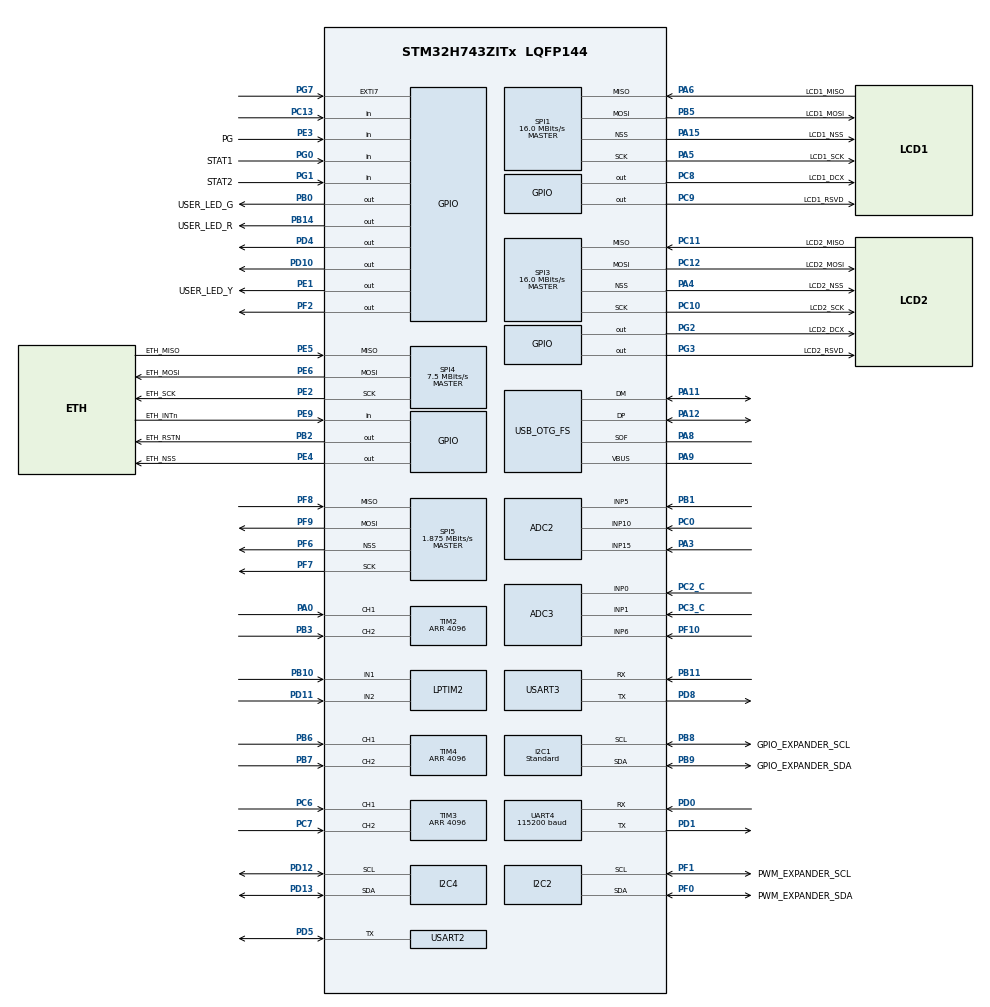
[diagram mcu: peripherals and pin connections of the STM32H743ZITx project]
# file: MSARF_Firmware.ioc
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ADC2.Channel-1\#ChannelRegularConversion=ADC_CHANNEL_15
ADC2.Channel-2\#ChannelRegularConversion=ADC_CHANNEL_5
ADC2.Channel-3\#ChannelRegularConversion=ADC_CHANNEL_5
ADC2.ContinuousConvMode=ENABLE
ADC2.ConversionDataManagement=ADC_CONVERSIONDATA_DR
ADC2.NbrOfConversion=3
ADC2.NbrOfConversionFlag=1
ADC2.OffsetNumber-1\#ChannelRegularConversion=ADC_OFFSET_NONE
ADC2.OffsetNumber-2\#ChannelRegularConversion=ADC_OFFSET_NONE
ADC2.OffsetNumber-3\#ChannelRegularConversion=ADC_OFFSET_NONE
ADC2.Rank-1\#ChannelRegularConversion=1
ADC2.Rank-2\#ChannelRegularConversion=2
ADC2.Rank-3\#ChannelRegularConversion=3
ADC2.SamplingTime-1\#ChannelRegularConversion=ADC_SAMPLETIME_64CYCLES_5
ADC2.SamplingTime-2\#ChannelRegularConversion=ADC_SAMPLETIME_64CYCLES_5
ADC2.SamplingTime-3\#ChannelRegularConversion=ADC_SAMPLETIME_64CYCLES_5
ADC3.Channel-0\#ChannelRegularConversion=ADC_CHANNEL_0
ADC3.Channel-1\#ChannelRegularConversion=ADC_CHANNEL_1
ADC3.Channel-2\#ChannelRegularConversion=ADC_CHANNEL_6
ADC3.ContinuousConvMode=ENABLE
ADC3.ConversionDataManagement=ADC_CONVERSIONDATA_DR
ADC3.EOCSelection=ADC_EOC_SINGLE_CONV
ADC3.NbrOfConversion=3
ADC3.NbrOfConversionFlag=1
ADC3.OffsetNumber-0\#ChannelRegularConversion=ADC_OFFSET_NONE
ADC3.OffsetNumber-1\#ChannelRegularConversion=ADC_OFFSET_NONE
ADC3.OffsetNumber-2\#ChannelRegularConversion=ADC_OFFSET_NONE
ADC3.Rank-0\#ChannelRegularConversion=1
ADC3.Rank-1\#ChannelRegularConversion=2
ADC3.Rank-2\#ChannelRegularConversion=3
ADC3.SamplingTime-0\#ChannelRegularConversion=ADC_SAMPLETIME_64CYCLES_5
ADC3.SamplingTime-1\#ChannelRegularConversion=ADC_SAMPLETIME_64CYCLES_5
ADC3.SamplingTime-2\#ChannelRegularConversion=ADC_SAMPLETIME_64CYCLES_5
CORTEX_M7.CPU_DCache=Enabled
CORTEX_M7.CPU_ICache=Enabled
CORTEX_M7.MPU_Control=MPU_PRIVILEGED_DEFAULT
DMA2D.ColorMode=DMA2D_OUTPUT_ARGB1555
Dma.Request0=SPI1_TX
Dma.Request1=SPI3_TX
Dma.SPI1_TX.0.Direction=DMA_MEMORY_TO_PERIPH
Dma.SPI1_TX.0.EventEnable=DISABLE
Dma.SPI1_TX.0.FIFOMode=DMA_FIFOMODE_DISABLE
Dma.SPI1_TX.0.Instance=DMA1_Stream4
Dma.SPI1_TX.0.MemDataAlignment=DMA_MDATAALIGN_BYTE
Dma.SPI1_TX.0.MemInc=DMA_MINC_ENABLE
Dma.SPI1_TX.0.Mode=DMA_NORMAL
Dma.SPI1_TX.0.PeriphDataAlignment=DMA_PDATAALIGN_BYTE
Dma.SPI1_TX.0.PeriphInc=DMA_PINC_DISABLE
Dma.SPI1_TX.0.Polarity=HAL_DMAMUX_REQ_GEN_RISING
Dma.SPI1_TX.0.Priority=DMA_PRIORITY_LOW
Dma.SPI1_TX.0.RequestNumber=1
Dma.SPI1_TX.0.SignalID=NONE
Dma.SPI1_TX.0.SyncEnable=DISABLE
Dma.SPI1_TX.0.SyncPolarity=HAL_DMAMUX_SYNC_NO_EVENT
Dma.SPI1_TX.0.SyncRequestNumber=1
Dma.SPI1_TX.0.SyncSignalID=NONE
Dma.SPI3_TX.1.Direction=DMA_MEMORY_TO_PERIPH
Dma.SPI3_TX.1.EventEnable=DISABLE
Dma.SPI3_TX.1.FIFOMode=DMA_FIFOMODE_DISABLE
Dma.SPI3_TX.1.Instance=DMA1_Stream0
Dma.SPI3_TX.1.MemDataAlignment=DMA_MDATAALIGN_BYTE
Dma.SPI3_TX.1.MemInc=DMA_MINC_ENABLE
Dma.SPI3_TX.1.Mode=DMA_NORMAL
Dma.SPI3_TX.1.PeriphDataAlignment=DMA_PDATAALIGN_BYTE
Dma.SPI3_TX.1.PeriphInc=DMA_PINC_DISABLE
Dma.SPI3_TX.1.Polarity=HAL_DMAMUX_REQ_GEN_RISING
Dma.SPI3_TX.1.Priority=DMA_PRIORITY_LOW
Dma.SPI3_TX.1.RequestNumber=1
Dma.SPI3_TX.1.SignalID=NONE
Dma.SPI3_TX.1.SyncEnable=DISABLE
Dma.SPI3_TX.1.SyncPolarity=HAL_DMAMUX_SYNC_NO_EVENT
Dma.SPI3_TX.1.SyncRequestNumber=1
Dma.SPI3_TX.1.SyncSignalID=NONE
FREERTOS.BinarySemaphores01=lcdDisplaysTaskSem,Dynamic,NULL;pidStepTaskSem,Dynamic,NULL
FREERTOS.HEAP_NUMBER=4
FREERTOS.INCLUDE_pcTaskGetTaskName=1
FREERTOS.INCLUDE_uxTaskGetStackHighWaterMark2=1
FREERTOS.INCLUDE_xTaskGetCurrentTaskHandle=1
FREERTOS.INCLUDE_xTaskGetHandle=1
FREERTOS.Tasks01=commTask,24,2048,StartCommTask,Default,NULL,Dynamic,NULL,NULL;lcdDisplaysTask,24,4096,StartLCDDisplays,Default,NULL,Dynamic,NULL,NULL;motorOutputTask,24,4096,StartMotorOutput,Default,NULL,Dynamic,NULL,NULL
FREERTOS.Timers01=Timer_LCD,Timer_LCD_cb,osTimerPeriodic,Default,NULL,Dynamic,NULL;Timer_PID,Timer_PID_cb,osTimerPeriodic,Default,NULL,Dynamic,NULL
FREERTOS.configENABLE_FPU=1
FREERTOS.configGENERATE_RUN_TIME_STATS=1
FREERTOS.configRECORD_STACK_HIGH_ADDRESS=1
FREERTOS.configTIMER_TASK_PRIORITY=55
FREERTOS.configTOTAL_HEAP_SIZE=512000
FREERTOS.configUSE_APPLICATION_TASK_TAG=1
FREERTOS.configUSE_STATS_FORMATTING_FUNCTIONS=1
HRTIM.CompareUnit1-MasterTimer=__NULL
HRTIM.Periode_MASTER=12000
HRTIM.PrescalerRatio_MASTER=HRTIM_PRESCALERRATIO_DIV1
I2C1.AddressingMode=I2C_ADDRESSINGMODE_7BIT
I2C1.I2C_Speed_Mode=I2C_Standard
I2C1.Timing=0x307075B1
I2C2.Timing=0x307075B1
I2C4.Timing=0x307075B1
Mcu.Family=STM32H7
Mcu.Name=STM32H743ZITx
Mcu.Package=LQFP144
NVIC.DMA1_Stream0_IRQn=true\:5\:0\:false\:false\:true\:true\:false\:true
NVIC.DMA1_Stream4_IRQn=true\:5\:0\:false\:false\:true\:true\:false\:true
NVIC.HRTIM1_Master_IRQn=true\:5\:0\:false\:false\:true\:true\:true\:true
NVIC.PriorityGroup=NVIC_PRIORITYGROUP_4
NVIC.SPI1_IRQn=true\:5\:0\:false\:false\:true\:true\:false\:true
NVIC.SPI3_IRQn=true\:5\:0\:false\:false\:true\:true\:false\:true
NVIC.TIM1_UP_IRQn=true\:0\:0\:false\:false\:true\:false\:false\:true
NVIC.TimeBase=TIM1_UP_IRQn
NVIC.TimeBaseIP=TIM1
PA0.Signal=S_TIM2_CH1_ETR
PA11.Mode=Device_Only
PA11.Signal=USB_OTG_FS_DM
PA12.Mode=Device_Only
PA12.Signal=USB_OTG_FS_DP
PA15\ (JTDI).GPIO_Label=LCD1_NSS
PA15\ (JTDI).Mode=NSS_Signal_Hard_Output
PA15\ (JTDI).Signal=SPI1_NSS
PA3.Signal=ADCx_INP15
PA4.GPIO_Label=LCD2_NSS
PA4.Mode=NSS_Signal_Hard_Output
PA4.Signal=SPI3_NSS
PA5.GPIO_Label=LCD1_SCK
PA5.Mode=Full_Duplex_Master
PA5.Signal=SPI1_SCK
PA6.GPIO_Label=LCD1_MISO
PA6.Mode=Full_Duplex_Master
PA6.Signal=SPI1_MISO
PA8.Mode=Activate_SOF_FS
PA8.Signal=USB_OTG_FS_SOF
PA9.Mode=Activate_VBUS
PA9.Signal=USB_OTG_FS_VBUS
PB0.GPIO_Label=USER_LED_G
PB0.Signal=GPIO_Output
PB1.Signal=ADCx_INP5
PB10.Mode=Encoder_mode_occur1
PB10.Signal=LPTIM2_IN1
PB11.Mode=Asynchronous
PB11.Signal=USART3_RX
PB14.GPIO_Label=USER_LED_R
PB14.GPIO_ModeDefaultOutputPP=GPIO_MODE_OUTPUT_PP
PB14.GPIO_PuPd=GPIO_NOPULL
PB14.GPIO_Speed=GPIO_SPEED_FREQ_LOW
PB14.PinState=GPIO_PIN_RESET
PB14.Signal=GPIO_Output
PB2.GPIO_Label=ETH_RSTN
PB2.GPIO_ModeDefaultOutputPP=GPIO_MODE_OUTPUT_PP
PB2.GPIO_PuPd=GPIO_NOPULL
PB2.GPIO_Speed=GPIO_SPEED_FREQ_LOW
PB2.PinState=GPIO_PIN_RESET
PB2.Signal=GPIO_Output
PB3\ (JTDO/TRACESWO).Signal=S_TIM2_CH2
PB5.GPIO_Label=LCD1_MOSI
PB5.Mode=Full_Duplex_Master
PB5.Signal=SPI1_MOSI
PB6.Signal=S_TIM4_CH1
PB7.Signal=S_TIM4_CH2
PB8.GPIO_Label=GPIO_EXPANDER_SCL
PB8.Mode=I2C
PB8.Signal=I2C1_SCL
PB9.GPIO_Label=GPIO_EXPANDER_SDA
PB9.Mode=I2C
PB9.Signal=I2C1_SDA
PC0.Signal=ADCx_INP10
PC10.GPIO_Label=LCD2_SCK
PC10.Mode=Full_Duplex_Master
PC10.Signal=SPI3_SCK
PC11.GPIO_Label=LCD2_MISO
PC11.Mode=Full_Duplex_Master
PC11.Signal=SPI3_MISO
PC12.GPIO_Label=LCD2_MOSI
PC12.Mode=Full_Duplex_Master
PC12.Signal=SPI3_MOSI
PC13.GPIO_Mode=GPIO_MODE_INPUT
PC13.GPIO_PuPd=GPIO_NOPULL
PC13.Signal=GPIO_Input
PC14-OSC32_IN\ (OSC32_IN).Mode=LSE-External-Oscillator
PC14-OSC32_IN\ (OSC32_IN).Signal=RCC_OSC32_IN
PC15-OSC32_OUT\ (OSC32_OUT).Mode=LSE-External-Oscillator
PC15-OSC32_OUT\ (OSC32_OUT).Signal=RCC_OSC32_OUT
PC2_C.Mode=IN0-Single-Ended
PC2_C.Signal=ADC3_INP0
PC3_C.Mode=IN1-Single-Ended
PC3_C.Signal=ADC3_INP1
PC6.Signal=S_TIM3_CH1
PC7.Signal=S_TIM3_CH2
PC8.GPIO_Label=LCD1_DCX
PC8.GPIO_ModeDefaultOutputPP=GPIO_MODE_OUTPUT_PP
PC8.GPIO_PuPd=GPIO_NOPULL
PC8.GPIO_Speed=GPIO_SPEED_FREQ_LOW
PC8.PinState=GPIO_PIN_RESET
PC8.Signal=GPIO_Output
PC9.GPIO_Label=LCD1_RSVD
PC9.GPIO_ModeDefaultOutputPP=GPIO_MODE_OUTPUT_PP
PC9.GPIO_PuPd=GPIO_NOPULL
PC9.GPIO_Speed=GPIO_SPEED_FREQ_LOW
PC9.PinState=GPIO_PIN_RESET
PC9.Signal=GPIO_Output
PD0.GPIO_PuPd=GPIO_NOPULL
PD0.GPIO_Speed=GPIO_SPEED_FREQ_LOW
PD0.Mode=Asynchronous
PD0.Signal=UART4_RX
PD1.GPIO_PuPd=GPIO_NOPULL
PD1.GPIO_Speed=GPIO_SPEED_FREQ_VERY_HIGH
PD1.Mode=Asynchronous
PD1.Signal=UART4_TX
PD10.GPIO_ModeDefaultOutputPP=GPIO_MODE_OUTPUT_PP
PD10.GPIO_PuPd=GPIO_NOPULL
PD10.GPIO_Speed=GPIO_SPEED_FREQ_LOW
PD10.PinState=GPIO_PIN_RESET
PD10.Signal=GPIO_Output
PD11.Mode=Encoder_mode_occur1
PD11.Signal=LPTIM2_IN2
PD12.Mode=I2C
PD12.Signal=I2C4_SCL
PD13.Mode=I2C
PD13.Signal=I2C4_SDA
PD4.PinState=GPIO_PIN_SET
PD4.Signal=GPIO_Output
PD5.Mode=Half_duplex(single_wire_mode)
PD5.Signal=USART2_TX
PD6.Signal=USART2_RX
PD7.Signal=USART2_CK
PD8.Mode=Asynchronous
PD8.Signal=USART3_TX
PE1.GPIO_Label=USER_LED_Y
PE1.Signal=GPIO_Output
PE2.GPIO_Label=ETH_SCK
PE2.Mode=Full_Duplex_Master
PE2.Signal=SPI4_SCK
PE3.GPIO_Label=PG
PE3.GPIO_Mode=GPIO_MODE_INPUT
PE3.GPIO_PuPd=GPIO_PULLUP
PE3.Signal=GPIO_Input
PE4.GPIO_Label=ETH_NSS
PE4.GPIO_ModeDefaultOutputPP=GPIO_MODE_OUTPUT_PP
PE4.GPIO_PuPd=GPIO_PULLUP
PE4.GPIO_Speed=GPIO_SPEED_FREQ_LOW
PE4.PinState=GPIO_PIN_RESET
PE4.Signal=GPIO_Output
PE5.GPIO_Label=ETH_MISO
PE5.Mode=Full_Duplex_Master
PE5.Signal=SPI4_MISO
PE6.GPIO_Label=ETH_MOSI
PE6.Mode=Full_Duplex_Master
PE6.Signal=SPI4_MOSI
PE9.GPIO_Label=ETH_INTn
PE9.GPIO_Mode=GPIO_MODE_INPUT
PE9.GPIO_PuPd=GPIO_NOPULL
PE9.Signal=GPIO_Input
PF0.GPIO_Label=PWM_EXPANDER_SDA
PF0.Mode=I2C
PF0.Signal=I2C2_SDA
PF1.GPIO_Label=PWM_EXPANDER_SCL
PF1.Mode=I2C
PF1.Signal=I2C2_SCL
PF10.Mode=IN6-Single-Ended
PF10.Signal=ADC3_INP6
PF2.Signal=GPIO_Output
PF6.Mode=NSS_Signal_Hard_Output
PF6.Signal=SPI5_NSS
PF7.GPIO_PuPd=GPIO_NOPULL
PF7.Mode=Full_Duplex_Master
PF7.Signal=SPI5_SCK
PF8.GPIO_PuPd=GPIO_PULLDOWN
PF8.Mode=Full_Duplex_Master
PF8.Signal=SPI5_MISO
PF9.GPIO_PuPd=GPIO_PULLDOWN
PF9.Mode=Full_Duplex_Master
PF9.Signal=SPI5_MOSI
PG0.GPIO_Label=STAT1
PG0.GPIO_PuPd=GPIO_PULLUP
PG0.Signal=GPIO_Input
PG1.GPIO_Label=STAT2
PG1.GPIO_Mode=GPIO_MODE_INPUT
PG1.GPIO_PuPd=GPIO_PULLUP
PG1.Signal=GPIO_Input
PG2.GPIO_Label=LCD2_DCX
PG2.Signal=GPIO_Output
PG3.GPIO_Label=LCD2_RSVD
PG3.GPIO_ModeDefaultOutputPP=GPIO_MODE_OUTPUT_PP
PG3.GPIO_PuPd=GPIO_NOPULL
PG3.GPIO_Speed=GPIO_SPEED_FREQ_LOW
PG3.PinState=GPIO_PIN_RESET
PG3.Signal=GPIO_Output
PG7.GPIO_ModeDefaultEXTI=GPIO_MODE_IT_RISING
PG7.GPIO_PuPd=GPIO_NOPULL
PG7.Signal=GPXTI7
PH0-OSC_IN\ (PH0).Mode=HSE-External-Oscillator
PH0-OSC_IN\ (PH0).Signal=RCC_OSC_IN
PH1-OSC_OUT\ (PH1).Mode=HSE-External-Oscillator
PH1-OSC_OUT\ (PH1).Signal=RCC_OSC_OUT
ProjectManager.HeapSize=0x200
ProjectManager.StackSize=0x400
ProjectManager.TargetToolchain=STM32CubeIDE
RCC.ADCFreq_Value=76000000
RCC.APB1Freq_Value=120000000
RCC.APB2Freq_Value=120000000
RCC.APB3Freq_Value=120000000
RCC.APB4Freq_Value=120000000
RCC.CortexFreq_Value=480000000
RCC.D1PPRE=RCC_APB3_DIV2
RCC.D2PPRE1=RCC_APB1_DIV2
RCC.D2PPRE2=RCC_APB2_DIV2
RCC.D3PPRE=RCC_APB4_DIV2
RCC.DIVM1=1
RCC.DIVM2=1
RCC.DIVN1=120
RCC.DIVN2=19
RCC.DIVQ1=20
RCC.HCLKFreq_Value=240000000
RCC.HPRE=RCC_HCLK_DIV2
RCC.HSE_VALUE=8000000
RCC.PLL2FRACN=0
RCC.PLL3FRACN=0
RCC.PLLFRACN=0
RCC.RCC_TIM_PRescaler_Selection=RCC_TIMPRES_DESACTIVATED
RCC.SPI123CLockSelection=RCC_SPI123CLKSOURCE_CLKP
RCC.SYSCLKFreq_VALUE=480000000
RCC.SYSCLKSource=RCC_SYSCLKSOURCE_PLLCLK
RCC.USBFreq_Value=48000000
SH.ADCx_INP10.0=ADC2_INP10,IN10-Single-Ended
SH.ADCx_INP15.0=ADC2_INP15,IN15-Single-Ended
SH.ADCx_INP5.0=ADC2_INP5,IN5-Single-Ended
SH.S_TIM2_CH1_ETR.0=TIM2_CH1,Encoder_Interface
SH.S_TIM2_CH2.0=TIM2_CH2,Encoder_Interface
SH.S_TIM3_CH1.0=TIM3_CH1,Encoder_Interface
SH.S_TIM3_CH2.0=TIM3_CH2,Encoder_Interface
SH.S_TIM4_CH1.0=TIM4_CH1,Encoder_Interface
SH.S_TIM4_CH2.0=TIM4_CH2,Encoder_Interface
SPI1.BaudRatePrescaler=SPI_BAUDRATEPRESCALER_4
SPI1.CLKPolarity=SPI_POLARITY_LOW
SPI1.CalculateBaudRate=16.0 MBits/s
SPI1.DataSize=SPI_DATASIZE_8BIT
SPI1.Direction=SPI_DIRECTION_2LINES
SPI1.FirstBit=SPI_FIRSTBIT_MSB
SPI1.Mode=SPI_MODE_MASTER
SPI1.VirtualNSS=VM_NSSHARD
SPI1.VirtualType=VM_MASTER
SPI3.BaudRatePrescaler=SPI_BAUDRATEPRESCALER_4
SPI3.CalculateBaudRate=16.0 MBits/s
SPI3.DataSize=SPI_DATASIZE_8BIT
SPI3.Direction=SPI_DIRECTION_2LINES
SPI3.Mode=SPI_MODE_MASTER
SPI3.VirtualNSS=VM_NSSHARD
SPI3.VirtualType=VM_MASTER
SPI4.BaudRatePrescaler=SPI_BAUDRATEPRESCALER_16
SPI4.CLKPhase=SPI_PHASE_2EDGE
SPI4.CLKPolarity=SPI_POLARITY_HIGH
SPI4.CalculateBaudRate=7.5 MBits/s
SPI4.DataSize=SPI_DATASIZE_8BIT
SPI4.Direction=SPI_DIRECTION_2LINES
SPI4.Mode=SPI_MODE_MASTER
SPI4.VirtualType=VM_MASTER
SPI5.BaudRatePrescaler=SPI_BAUDRATEPRESCALER_64
SPI5.CLKPhase=SPI_PHASE_2EDGE
SPI5.CLKPolarity=SPI_POLARITY_LOW
SPI5.CalculateBaudRate=1.875 MBits/s
SPI5.DataSize=SPI_DATASIZE_8BIT
SPI5.Direction=SPI_DIRECTION_2LINES
SPI5.MasterKeepIOState=SPI_MASTER_KEEP_IO_STATE_ENABLE
SPI5.Mode=SPI_MODE_MASTER
SPI5.VirtualNSS=VM_NSSHARD
SPI5.VirtualType=VM_MASTER
TIM2.IC1Filter=5
TIM2.IC2Filter=5
TIM2.Period=4096
TIM3.IC1Filter=5
TIM3.IC2Filter=5
TIM3.Period=4096
TIM4.IC1Filter=5
TIM4.IC2Filter=5
TIM4.Period=4096
UART4.BaudRate=115200
UART4.ClockPrescaler=PRESCALER_DIV1
UART4.DMADisableonRxErrorParam=UART_ADVFEATURE_DMA_ENABLEONRXERROR
UART4.FIFOMode=FIFOMODE_ENABLE
UART4.OverrunDisableParam=UART_ADVFEATURE_OVERRUN_ENABLE
UART4.RXFIFOThreshold=RXFIFO_THRESHOLD_HALFFULL
UART4.RxPinLevelInvertParam=UART_ADVFEATURE_RXINV_DISABLE
UART4.SwapParam=UART_ADVFEATURE_SWAP_DISABLE
UART4.TXFIFOThreshold=TXFIFO_THRESHOLD_HALFFULL
UART4.WordLength=WORDLENGTH_8B
USART2.VirtualMode-Half_duplex(single_wire_mode)=VM_ASYNC
USART3.VirtualMode-Asynchronous=VM_ASYNC
USB_OTG_FS.VirtualMode=Device_Only
VP_DMA2D_VS_DMA2D.Mode=DMA2D_Activate
VP_FREERTOS_VS_CMSIS_V2.Mode=CMSIS_V2
VP_HRTIM_VS_hrtimMasterTimerNoOutput.Mode=MasterTimer
VP_SYS_VS_tim1.Mode=TIM1
board=NUCLEO-H743ZI2

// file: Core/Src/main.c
/* USER CODE BEGIN Header */
/**
 ******************************************************************************
 * @file           : main.c
 * @brief          : Main program body
 ******************************************************************************
 * @attention
 *
 * <h2><center>&copy; Copyright (c) 2019 STMicroelectronics.
 * All rights reserved.</center></h2>
 *
 * This software component is licensed by ST under BSD 3-Clause license,
 * the "License"; You may not use this file except in compliance with the
 * License. You may obtain a copy of the License at:
 *                        opensource.org/licenses/BSD-3-Clause
 *
 ******************************************************************************
 */
/* USER CODE END Header */
#include "main.h"
#include "cmsis_os.h"

/* USER CODE BEGIN Includes */
#include "ST7789Wrapper.h"

#include "Xavier.h"

#include "PackageWrapper.h"

#include "Ethernet_Driver.h"
#include "eye_80x80.h"

#include <stdlib.h>
#include <stdio.h>
/* USER CODE END Includes */

/* USER CODE BEGIN PD */
#define ever ;;
//#define DO_LOOP_MEASURE 1
/* USER CODE END PD */

ADC_HandleTypeDef hadc2;
ADC_HandleTypeDef hadc3;

DMA2D_HandleTypeDef hdma2d;

HRTIM_HandleTypeDef hhrtim;

I2C_HandleTypeDef hi2c1;
I2C_HandleTypeDef hi2c2;
I2C_HandleTypeDef hi2c4;

LPTIM_HandleTypeDef hlptim2;

SPI_HandleTypeDef hspi1;
SPI_HandleTypeDef hspi3;
SPI_HandleTypeDef hspi4;
SPI_HandleTypeDef hspi5;
DMA_HandleTypeDef hdma_spi1_tx;
DMA_HandleTypeDef hdma_spi3_tx;

TIM_HandleTypeDef htim2;
TIM_HandleTypeDef htim3;
TIM_HandleTypeDef htim4;

UART_HandleTypeDef huart4;
UART_HandleTypeDef huart2;
UART_HandleTypeDef huart3;

USART_HandleTypeDef husart2;

PCD_HandleTypeDef hpcd_USB_OTG_FS;

/* Definitions for commTask */
osThreadId_t commTaskHandle;
const osThreadAttr_t commTask_attributes = {
  .name = "commTask",
  .stack_size = 2048 * 4,
  .priority = (osPriority_t) osPriorityNormal,
};
/* Definitions for lcdDisplaysTask */
osThreadId_t lcdDisplaysTaskHandle;
const osThreadAttr_t lcdDisplaysTask_attributes = {
  .name = "lcdDisplaysTask",
  .stack_size = 4096 * 4,
  .priority = (osPriority_t) osPriorityNormal,
};
/* Definitions for motorOutputTask */
osThreadId_t motorOutputTaskHandle;
const osThreadAttr_t motorOutputTask_attributes = {
  .name = "motorOutputTask",
  .stack_size = 4096 * 4,
  .priority = (osPriority_t) osPriorityNormal,
};
/* Definitions for Timer_LCD */
osTimerId_t Timer_LCDHandle;
const osTimerAttr_t Timer_LCD_attributes = {
  .name = "Timer_LCD"
};
/* Definitions for Timer_PID */
osTimerId_t Timer_PIDHandle;
const osTimerAttr_t Timer_PID_attributes = {
  .name = "Timer_PID"
};
/* Definitions for lcdDisplaysTaskSem */
osSemaphoreId_t lcdDisplaysTaskSemHandle;
const osSemaphoreAttr_t lcdDisplaysTaskSem_attributes = {
  .name = "lcdDisplaysTaskSem"
};
/* Definitions for pidStepTaskSem */
osSemaphoreId_t pidStepTaskSemHandle;
const osSemaphoreAttr_t pidStepTaskSem_attributes = {
  .name = "pidStepTaskSem"
};

void SystemClock_Config(void);
void PeriphCommonClock_Config(void);
static void MPU_Config(void);
static void MX_GPIO_Init(void);
static void MX_DMA_Init(void);
static void MX_USB_OTG_FS_PCD_Init(void);
static void MX_SPI4_Init(void);
static void MX_SPI1_Init(void);
static void MX_DMA2D_Init(void);
static void MX_I2C1_Init(void);
static void MX_I2C2_Init(void);
static void MX_UART4_Init(void);
static void MX_LPTIM2_Init(void);
static void MX_SPI3_Init(void);
static void MX_SPI5_Init(void);
static void MX_USART2_UART_Init(void);
static void MX_I2C4_Init(void);
static void MX_TIM2_Init(void);
static void MX_TIM3_Init(void);
static void MX_TIM4_Init(void);
static void MX_HRTIM_Init(void);
static void MX_ADC3_Init(void);
static void MX_USART3_UART_Init(void);
static void MX_ADC2_Init(void);
void StartCommTask(void *argument);
void StartLCDDisplays(void *argument);
void StartMotorOutput(void *argument);
void Timer_LCD_cb(void *argument);
void Timer_PID_cb(void *argument);

/* USER CODE BEGIN PFP */
void FillRectHandle(void);
void BlendImageHandle(void);
/* USER CODE END PFP */

/* USER CODE BEGIN 0 */
uint8_t generic_st7789[] = {      // Init commands for 7789 screens
		9,                                  //  9 commands in list:
				ST77XX_SWRESET, ST_CMD_DELAY, //  1: Software reset, no args, w/delay
				150,                            //     ~150 ms delay
				ST77XX_SLPOUT, ST_CMD_DELAY, //  2: Out of sleep mode, no args, w/delay
				10,                             //      10 ms delay
				ST77XX_COLMOD, 1 + ST_CMD_DELAY, //  3: Set color mode, 1 arg + delay:
				0x55,                           //     16-bit color
				10,                             //     10 ms delay
				ST77XX_MADCTL, 1, //  4: Mem access ctrl (directions), 1 arg:
				0x58,                //     Row/col addr, bottom-top refresh
				ST77XX_CASET, 4,   //  5: Column addr set, 4 args, no delay:
				0x00, 0,                        //     XSTART = 0
				0, 240,                         //     XEND = 240
				ST77XX_RASET, 4,      //  6: Row addr set, 4 args, no delay:
				0x00, 0,                        //     YSTART = 0
				320 >> 8, 320 & 0xFF,                     //     YEND = 320
				ST77XX_INVON, ST_CMD_DELAY,         //  7: hack
				10,
				ST77XX_NORON, ST_CMD_DELAY, //  8: Normal display on, no args, w/delay
				10,                             //     10 ms delay
				ST77XX_DISPON, ST_CMD_DELAY, //  9: Main screen turn on, no args, delay
				10 };

struct ST7789 *lcd1;
struct ST7789 *lcd2;

struct GPIOBank *_GPIOBank;
struct PWMBank *_PWMBank;

#define MAX_PACKAGES 255
struct Package *Packages[MAX_PACKAGES];

uint16_t *lcd1_screen_buffer;
uint16_t *lcd2_screen_buffer;

int32_t timer_count = 0;

uint32_t ADC_buff[6];
uint32_t val[6];

DMA2D_HandleTypeDef fillRectHandle;
DMA2D_HandleTypeDef blendImageHandle;

uint8_t lcd1_x_t = 50;
uint8_t lcd1_y_t = 50;
uint8_t lcd2_x_t = 50;
uint8_t lcd2_y_t = 50;

uint8_t blink = 0;

//void HAL_ADC_ConvCpltCallback(ADC_HandleTypeDef *hadc){
//	if(hadc->Instance == ADC2){
//		val[0] = ADC_buff[0];
//		val[1] = ADC_buff[1];
//		val[2] = ADC_buff[2];
//	}else if(hadc->Instance == ADC3){
//		val[3] = ADC_buff[3];
//		val[4] = ADC_buff[4];
//		val[5] = ADC_buff[5];
//	}
//}

volatile bool oneTransmitting = false;
volatile bool threeTransmitting = false;

void HAL_SPI_TxCpltCallback(SPI_HandleTypeDef *hspi){
	if(hspi->Instance == SPI1){
		oneTransmitting = false;
	}else if(hspi->Instance == SPI3){
		threeTransmitting = false;
	}
}

/* USER CODE END 0 */

int main(void)
{

  /* MPU Configuration--------------------------------------------------------*/
  MPU_Config();

  /* Enable I-Cache---------------------------------------------------------*/
  SCB_EnableICache();

  /* Enable D-Cache---------------------------------------------------------*/
  SCB_EnableDCache();

  /* MCU Configuration--------------------------------------------------------*/

  /* Reset of all peripherals, Initializes the Flash interface and the Systick. */
  HAL_Init();

  /* Configure the system clock */
  SystemClock_Config();

/* Configure the peripherals common clocks */
  PeriphCommonClock_Config();

  /* Initialize all configured peripherals */
  MX_GPIO_Init();
  MX_DMA_Init();
  MX_USB_OTG_FS_PCD_Init();
  MX_SPI4_Init();
  MX_SPI1_Init();
  MX_DMA2D_Init();
  MX_I2C1_Init();
  MX_I2C2_Init();
  MX_UART4_Init();
  MX_LPTIM2_Init();
  MX_SPI3_Init();
  MX_SPI5_Init();
  MX_USART2_UART_Init();
  MX_I2C4_Init();
  MX_TIM2_Init();
  MX_TIM3_Init();
  MX_TIM4_Init();
  MX_HRTIM_Init();
  MX_ADC3_Init();
  MX_USART3_UART_Init();
  MX_ADC2_Init();
  /* USER CODE BEGIN 2 */
  FillRectHandle();
  BlendImageHandle();

	HAL_HRTIM_SimpleBaseStart_IT(&hhrtim, HRTIM_TIMERINDEX_MASTER);
  /* USER CODE END 2 */

  /* Init scheduler */
  osKernelInitialize();

  /* Create the semaphores(s) */
  /* creation of lcdDisplaysTaskSem */
  lcdDisplaysTaskSemHandle = osSemaphoreNew(1, 1, &lcdDisplaysTaskSem_attributes);

  /* creation of pidStepTaskSem */
  pidStepTaskSemHandle = osSemaphoreNew(1, 1, &pidStepTaskSem_attributes);

  /* Create the timer(s) */
  /* creation of Timer_LCD */
  Timer_LCDHandle = osTimerNew(Timer_LCD_cb, osTimerPeriodic, NULL, &Timer_LCD_attributes);

  /* creation of Timer_PID */
  Timer_PIDHandle = osTimerNew(Timer_PID_cb, osTimerPeriodic, NULL, &Timer_PID_attributes);

  /* USER CODE BEGIN RTOS_TIMERS */
	osStatus Timer_LCD_status = osTimerStart(Timer_LCDHandle, 33u);
	if(Timer_LCD_status != osOK){
	//timer didnt start
		timer_count = -1;
	}

	osStatus Timer_PID_status = osTimerStart(Timer_PIDHandle, 30u);
	if(Timer_PID_status != osOK){
	//timer didnt start
		timer_count = -1;
	}

	/* start timers, add new ones, ... */
  /* USER CODE END RTOS_TIMERS */

  /* Create the thread(s) */
  /* creation of commTask */
  commTaskHandle = osThreadNew(StartCommTask, NULL, &commTask_attributes);

  /* creation of lcdDisplaysTask */
  lcdDisplaysTaskHandle = osThreadNew(StartLCDDisplays, NULL, &lcdDisplaysTask_attributes);

  /* creation of motorOutputTask */
  motorOutputTaskHandle = osThreadNew(StartMotorOutput, NULL, &motorOutputTask_attributes);

  /* USER CODE BEGIN RTOS_THREADS */
	osThreadSuspend(lcdDisplaysTaskHandle);
	osThreadSuspend(motorOutputTaskHandle);
	/* add threads, ... */
  /* USER CODE END RTOS_THREADS */

  /* Start scheduler */
  osKernelStart();

  /* We should never get here as control is now taken by the scheduler */
  /* Infinite loop */
	while (1) {

	}
}

void SystemClock_Config(void)
{
  RCC_OscInitTypeDef RCC_OscInitStruct = {0};
  RCC_ClkInitTypeDef RCC_ClkInitStruct = {0};

  /** Supply configuration update enable
  */
  HAL_PWREx_ConfigSupply(PWR_LDO_SUPPLY);
  /** Configure the main internal regulator output voltage
  */
  __HAL_PWR_VOLTAGESCALING_CONFIG(PWR_REGULATOR_VOLTAGE_SCALE0);

  while(!__HAL_PWR_GET_FLAG(PWR_FLAG_VOSRDY)) {}
  /** Macro to configure the PLL clock source
  */
  __HAL_RCC_PLL_PLLSOURCE_CONFIG(RCC_PLLSOURCE_HSE);
  /** Initializes the RCC Oscillators according to the specified parameters
  * in the RCC_OscInitTypeDef structure.
  */
  RCC_OscInitStruct.OscillatorType = RCC_OSCILLATORTYPE_HSI|RCC_OSCILLATORTYPE_HSE;
  RCC_OscInitStruct.HSEState = RCC_HSE_ON;
  RCC_OscInitStruct.HSIState = RCC_HSI_DIV1;
  RCC_OscInitStruct.HSICalibrationValue = RCC_HSICALIBRATION_DEFAULT;
  RCC_OscInitStruct.PLL.PLLState = RCC_PLL_ON;
  RCC_OscInitStruct.PLL.PLLSource = RCC_PLLSOURCE_HSE;
  RCC_OscInitStruct.PLL.PLLM = 1;
  RCC_OscInitStruct.PLL.PLLN = 120;
  RCC_OscInitStruct.PLL.PLLP = 2;
  RCC_OscInitStruct.PLL.PLLQ = 20;
  RCC_OscInitStruct.PLL.PLLR = 2;
  RCC_OscInitStruct.PLL.PLLRGE = RCC_PLL1VCIRANGE_3;
  RCC_OscInitStruct.PLL.PLLVCOSEL = RCC_PLL1VCOWIDE;
  RCC_OscInitStruct.PLL.PLLFRACN = 0;
  if (HAL_RCC_OscConfig(&RCC_OscInitStruct) != HAL_OK)
  {
    Error_Handler();
  }
  /** Initializes the CPU, AHB and APB buses clocks
  */
  RCC_ClkInitStruct.ClockType = RCC_CLOCKTYPE_HCLK|RCC_CLOCKTYPE_SYSCLK
                              |RCC_CLOCKTYPE_PCLK1|RCC_CLOCKTYPE_PCLK2
                              |RCC_CLOCKTYPE_D3PCLK1|RCC_CLOCKTYPE_D1PCLK1;
  RCC_ClkInitStruct.SYSCLKSource = RCC_SYSCLKSOURCE_PLLCLK;
  RCC_ClkInitStruct.SYSCLKDivider = RCC_SYSCLK_DIV1;
  RCC_ClkInitStruct.AHBCLKDivider = RCC_HCLK_DIV2;
  RCC_ClkInitStruct.APB3CLKDivider = RCC_APB3_DIV2;
  RCC_ClkInitStruct.APB1CLKDivider = RCC_APB1_DIV2;
  RCC_ClkInitStruct.APB2CLKDivider = RCC_APB2_DIV2;
  RCC_ClkInitStruct.APB4CLKDivider = RCC_APB4_DIV2;

  if (HAL_RCC_ClockConfig(&RCC_ClkInitStruct, FLASH_LATENCY_4) != HAL_OK)
  {
    Error_Handler();
  }
}

void PeriphCommonClock_Config(void)
{
  RCC_PeriphCLKInitTypeDef PeriphClkInitStruct = {0};

  /** Initializes the peripherals clock
  */
  PeriphClkInitStruct.PeriphClockSelection = RCC_PERIPHCLK_ADC|RCC_PERIPHCLK_CKPER;
  PeriphClkInitStruct.PLL2.PLL2M = 1;
  PeriphClkInitStruct.PLL2.PLL2N = 19;
  PeriphClkInitStruct.PLL2.PLL2P = 2;
  PeriphClkInitStruct.PLL2.PLL2Q = 2;
  PeriphClkInitStruct.PLL2.PLL2R = 2;
  PeriphClkInitStruct.PLL2.PLL2RGE = RCC_PLL2VCIRANGE_3;
  PeriphClkInitStruct.PLL2.PLL2VCOSEL = RCC_PLL2VCOMEDIUM;
  PeriphClkInitStruct.PLL2.PLL2FRACN = 0;
  PeriphClkInitStruct.CkperClockSelection = RCC_CLKPSOURCE_HSI;
  PeriphClkInitStruct.AdcClockSelection = RCC_ADCCLKSOURCE_PLL2;
  if (HAL_RCCEx_PeriphCLKConfig(&PeriphClkInitStruct) != HAL_OK)
  {
    Error_Handler();
  }
}

static void MX_ADC2_Init(void)
{

  ADC_ChannelConfTypeDef sConfig = {0};

  /** Common config
  */
  hadc2.Instance = ADC2;
  hadc2.Init.ClockPrescaler = ADC_CLOCK_ASYNC_DIV1;
  hadc2.Init.Resolution = ADC_RESOLUTION_16B;
  hadc2.Init.ScanConvMode = ADC_SCAN_ENABLE;
  hadc2.Init.EOCSelection = ADC_EOC_SINGLE_CONV;
  hadc2.Init.LowPowerAutoWait = DISABLE;
  hadc2.Init.ContinuousConvMode = ENABLE;
  hadc2.Init.NbrOfConversion = 3;
  hadc2.Init.DiscontinuousConvMode = DISABLE;
  hadc2.Init.ExternalTrigConv = ADC_SOFTWARE_START;
  hadc2.Init.ExternalTrigConvEdge = ADC_EXTERNALTRIGCONVEDGE_NONE;
  hadc2.Init.ConversionDataManagement = ADC_CONVERSIONDATA_DR;
  hadc2.Init.Overrun = ADC_OVR_DATA_PRESERVED;
  hadc2.Init.LeftBitShift = ADC_LEFTBITSHIFT_NONE;
  hadc2.Init.OversamplingMode = DISABLE;
  if (HAL_ADC_Init(&hadc2) != HAL_OK)
  {
    Error_Handler();
  }
  /** Configure Regular Channel
  */
  sConfig.Channel = ADC_CHANNEL_15;
  sConfig.Rank = ADC_REGULAR_RANK_1;
  sConfig.SamplingTime = ADC_SAMPLETIME_64CYCLES_5;
  sConfig.SingleDiff = ADC_SINGLE_ENDED;
  sConfig.OffsetNumber = ADC_OFFSET_NONE;
  sConfig.Offset = 0;
  sConfig.OffsetSignedSaturation = DISABLE;
  if (HAL_ADC_ConfigChannel(&hadc2, &sConfig) != HAL_OK)
  {
    Error_Handler();
  }
  /** Configure Regular Channel
  */
  sConfig.Channel = ADC_CHANNEL_5;
  sConfig.Rank = ADC_REGULAR_RANK_2;
  if (HAL_ADC_ConfigChannel(&hadc2, &sConfig) != HAL_OK)
  {
    Error_Handler();
  }
  /** Configure Regular Channel
  */
  sConfig.Rank = ADC_REGULAR_RANK_3;
  if (HAL_ADC_ConfigChannel(&hadc2, &sConfig) != HAL_OK)
  {
    Error_Handler();
  }

}

static void MX_ADC3_Init(void)
{

  ADC_ChannelConfTypeDef sConfig = {0};

  /** Common config
  */
  hadc3.Instance = ADC3;
  hadc3.Init.ClockPrescaler = ADC_CLOCK_ASYNC_DIV1;
  hadc3.Init.Resolution = ADC_RESOLUTION_16B;
  hadc3.Init.ScanConvMode = ADC_SCAN_ENABLE;
  hadc3.Init.EOCSelection = ADC_EOC_SINGLE_CONV;
  hadc3.Init.LowPowerAutoWait = DISABLE;
  hadc3.Init.ContinuousConvMode = ENABLE;
  hadc3.Init.NbrOfConversion = 3;
  hadc3.Init.DiscontinuousConvMode = DISABLE;
  hadc3.Init.ExternalTrigConv = ADC_SOFTWARE_START;
  hadc3.Init.ExternalTrigConvEdge = ADC_EXTERNALTRIGCONVEDGE_NONE;
  hadc3.Init.ConversionDataManagement = ADC_CONVERSIONDATA_DR;
  hadc3.Init.Overrun = ADC_OVR_DATA_PRESERVED;
  hadc3.Init.LeftBitShift = ADC_LEFTBITSHIFT_NONE;
  hadc3.Init.OversamplingMode = DISABLE;
  if (HAL_ADC_Init(&hadc3) != HAL_OK)
  {
    Error_Handler();
  }
  /** Configure Regular Channel
  */
  sConfig.Channel = ADC_CHANNEL_0;
  sConfig.Rank = ADC_REGULAR_RANK_1;
  sConfig.SamplingTime = ADC_SAMPLETIME_64CYCLES_5;
  sConfig.SingleDiff = ADC_SINGLE_ENDED;
  sConfig.OffsetNumber = ADC_OFFSET_NONE;
  sConfig.Offset = 0;
  sConfig.OffsetSignedSaturation = DISABLE;
  if (HAL_ADC_ConfigChannel(&hadc3, &sConfig) != HAL_OK)
  {
    Error_Handler();
  }
  /** Configure Regular Channel
  */
  sConfig.Channel = ADC_CHANNEL_1;
  sConfig.Rank = ADC_REGULAR_RANK_2;
  if (HAL_ADC_ConfigChannel(&hadc3, &sConfig) != HAL_OK)
  {
    Error_Handler();
  }
  /** Configure Regular Channel
  */
  sConfig.Channel = ADC_CHANNEL_6;
  sConfig.Rank = ADC_REGULAR_RANK_3;
  if (HAL_ADC_ConfigChannel(&hadc3, &sConfig) != HAL_OK)
  {
    Error_Handler();
  }

}

static void MX_DMA2D_Init(void)
{

  hdma2d.Instance = DMA2D;
  hdma2d.Init.Mode = DMA2D_M2M;
  hdma2d.Init.ColorMode = DMA2D_OUTPUT_ARGB1555;
  hdma2d.Init.OutputOffset = 0;
  hdma2d.LayerCfg[1].InputOffset = 0;
  hdma2d.LayerCfg[1].InputColorMode = DMA2D_INPUT_ARGB1555;
  hdma2d.LayerCfg[1].AlphaMode = DMA2D_NO_MODIF_ALPHA;
  hdma2d.LayerCfg[1].InputAlpha = 0;
  hdma2d.LayerCfg[1].AlphaInverted = DMA2D_REGULAR_ALPHA;
  hdma2d.LayerCfg[1].RedBlueSwap = DMA2D_RB_REGULAR;
  hdma2d.LayerCfg[1].ChromaSubSampling = DMA2D_NO_CSS;
  if (HAL_DMA2D_Init(&hdma2d) != HAL_OK)
  {
    Error_Handler();
  }
  if (HAL_DMA2D_ConfigLayer(&hdma2d, 1) != HAL_OK)
  {
    Error_Handler();
  }

}

static void MX_HRTIM_Init(void)
{

  HRTIM_TimeBaseCfgTypeDef pTimeBaseCfg = {0};
  HRTIM_TimerCfgTypeDef pTimerCfg = {0};

  hhrtim.Instance = HRTIM1;
  hhrtim.Init.HRTIMInterruptResquests = HRTIM_IT_NONE;
  hhrtim.Init.SyncOptions = HRTIM_SYNCOPTION_NONE;
  if (HAL_HRTIM_Init(&hhrtim) != HAL_OK)
  {
    Error_Handler();
  }
  pTimeBaseCfg.Period = 12000;
  pTimeBaseCfg.RepetitionCounter = 0x00;
  pTimeBaseCfg.PrescalerRatio = HRTIM_PRESCALERRATIO_DIV1;
  pTimeBaseCfg.Mode = HRTIM_MODE_CONTINUOUS;
  if (HAL_HRTIM_TimeBaseConfig(&hhrtim, HRTIM_TIMERINDEX_MASTER, &pTimeBaseCfg) != HAL_OK)
  {
    Error_Handler();
  }
  pTimerCfg.InterruptRequests = HRTIM_MASTER_IT_NONE;
  pTimerCfg.DMARequests = HRTIM_MASTER_DMA_NONE;
  pTimerCfg.DMASrcAddress = 0x0000;
  pTimerCfg.DMADstAddress = 0x0000;
  pTimerCfg.DMASize = 0x1;
  pTimerCfg.HalfModeEnable = HRTIM_HALFMODE_DISABLED;
  pTimerCfg.StartOnSync = HRTIM_SYNCSTART_DISABLED;
  pTimerCfg.ResetOnSync = HRTIM_SYNCRESET_DISABLED;
  pTimerCfg.DACSynchro = HRTIM_DACSYNC_NONE;
  pTimerCfg.PreloadEnable = HRTIM_PRELOAD_DISABLED;
  pTimerCfg.UpdateGating = HRTIM_UPDATEGATING_INDEPENDENT;
  pTimerCfg.BurstMode = HRTIM_TIMERBURSTMODE_MAINTAINCLOCK;
  pTimerCfg.RepetitionUpdate = HRTIM_UPDATEONREPETITION_DISABLED;
  if (HAL_HRTIM_WaveformTimerConfig(&hhrtim, HRTIM_TIMERINDEX_MASTER, &pTimerCfg) != HAL_OK)
  {
    Error_Handler();
  }

}

static void MX_I2C1_Init(void)
{

  hi2c1.Instance = I2C1;
  hi2c1.Init.Timing = 0x307075B1;
  hi2c1.Init.OwnAddress1 = 0;
  hi2c1.Init.AddressingMode = I2C_ADDRESSINGMODE_7BIT;
  hi2c1.Init.DualAddressMode = I2C_DUALADDRESS_DISABLE;
  hi2c1.Init.OwnAddress2 = 0;
  hi2c1.Init.OwnAddress2Masks = I2C_OA2_NOMASK;
  hi2c1.Init.GeneralCallMode = I2C_GENERALCALL_DISABLE;
  hi2c1.Init.NoStretchMode = I2C_NOSTRETCH_DISABLE;
  if (HAL_I2C_Init(&hi2c1) != HAL_OK)
  {
    Error_Handler();
  }
  /** Configure Analogue filter
  */
  if (HAL_I2CEx_ConfigAnalogFilter(&hi2c1, I2C_ANALOGFILTER_ENABLE) != HAL_OK)
  {
    Error_Handler();
  }
  /** Configure Digital filter
  */
  if (HAL_I2CEx_ConfigDigitalFilter(&hi2c1, 0) != HAL_OK)
  {
    Error_Handler();
  }

}

static void MX_I2C2_Init(void)
{

  hi2c2.Instance = I2C2;
  hi2c2.Init.Timing = 0x307075B1;
  hi2c2.Init.OwnAddress1 = 0;
  hi2c2.Init.AddressingMode = I2C_ADDRESSINGMODE_7BIT;
  hi2c2.Init.DualAddressMode = I2C_DUALADDRESS_DISABLE;
  hi2c2.Init.OwnAddress2 = 0;
  hi2c2.Init.OwnAddress2Masks = I2C_OA2_NOMASK;
  hi2c2.Init.GeneralCallMode = I2C_GENERALCALL_DISABLE;
  hi2c2.Init.NoStretchMode = I2C_NOSTRETCH_DISABLE;
  if (HAL_I2C_Init(&hi2c2) != HAL_OK)
  {
    Error_Handler();
  }
  /** Configure Analogue filter
  */
  if (HAL_I2CEx_ConfigAnalogFilter(&hi2c2, I2C_ANALOGFILTER_ENABLE) != HAL_OK)
  {
    Error_Handler();
  }
  /** Configure Digital filter
  */
  if (HAL_I2CEx_ConfigDigitalFilter(&hi2c2, 0) != HAL_OK)
  {
    Error_Handler();
  }

}

static void MX_I2C4_Init(void)
{

  hi2c4.Instance = I2C4;
  hi2c4.Init.Timing = 0x307075B1;
  hi2c4.Init.OwnAddress1 = 0;
  hi2c4.Init.AddressingMode = I2C_ADDRESSINGMODE_7BIT;
  hi2c4.Init.DualAddressMode = I2C_DUALADDRESS_DISABLE;
  hi2c4.Init.OwnAddress2 = 0;
  hi2c4.Init.OwnAddress2Masks = I2C_OA2_NOMASK;
  hi2c4.Init.GeneralCallMode = I2C_GENERALCALL_DISABLE;
  hi2c4.Init.NoStretchMode = I2C_NOSTRETCH_DISABLE;
  if (HAL_I2C_Init(&hi2c4) != HAL_OK)
  {
    Error_Handler();
  }
  /** Configure Analogue filter
  */
  if (HAL_I2CEx_ConfigAnalogFilter(&hi2c4, I2C_ANALOGFILTER_ENABLE) != HAL_OK)
  {
    Error_Handler();
  }
  /** Configure Digital filter
  */
  if (HAL_I2CEx_ConfigDigitalFilter(&hi2c4, 0) != HAL_OK)
  {
    Error_Handler();
  }

}

static void MX_LPTIM2_Init(void)
{

  hlptim2.Instance = LPTIM2;
  hlptim2.Init.Clock.Source = LPTIM_CLOCKSOURCE_APBCLOCK_LPOSC;
  hlptim2.Init.Clock.Prescaler = LPTIM_PRESCALER_DIV1;
  hlptim2.Init.UltraLowPowerClock.Polarity = LPTIM_CLOCKPOLARITY_RISING;
  hlptim2.Init.UltraLowPowerClock.SampleTime = LPTIM_CLOCKSAMPLETIME_DIRECTTRANSITION;
  hlptim2.Init.Trigger.Source = LPTIM_TRIGSOURCE_SOFTWARE;
  hlptim2.Init.OutputPolarity = LPTIM_OUTPUTPOLARITY_HIGH;
  hlptim2.Init.UpdateMode = LPTIM_UPDATE_IMMEDIATE;
  hlptim2.Init.CounterSource = LPTIM_COUNTERSOURCE_EXTERNAL;
  hlptim2.Init.Input1Source = LPTIM_INPUT1SOURCE_GPIO;
  hlptim2.Init.Input2Source = LPTIM_INPUT2SOURCE_GPIO;
  if (HAL_LPTIM_Init(&hlptim2) != HAL_OK)
  {
    Error_Handler();
  }

}

static void MX_SPI1_Init(void)
{

  /* SPI1 parameter configuration*/
  hspi1.Instance = SPI1;
  hspi1.Init.Mode = SPI_MODE_MASTER;
  hspi1.Init.Direction = SPI_DIRECTION_2LINES;
  hspi1.Init.DataSize = SPI_DATASIZE_8BIT;
  hspi1.Init.CLKPolarity = SPI_POLARITY_LOW;
  hspi1.Init.CLKPhase = SPI_PHASE_1EDGE;
  hspi1.Init.NSS = SPI_NSS_HARD_OUTPUT;
  hspi1.Init.BaudRatePrescaler = SPI_BAUDRATEPRESCALER_4;
  hspi1.Init.FirstBit = SPI_FIRSTBIT_MSB;
  hspi1.Init.TIMode = SPI_TIMODE_DISABLE;
  hspi1.Init.CRCCalculation = SPI_CRCCALCULATION_DISABLE;
  hspi1.Init.CRCPolynomial = 0x0;
  hspi1.Init.NSSPMode = SPI_NSS_PULSE_ENABLE;
  hspi1.Init.NSSPolarity = SPI_NSS_POLARITY_LOW;
  hspi1.Init.FifoThreshold = SPI_FIFO_THRESHOLD_01DATA;
  hspi1.Init.TxCRCInitializationPattern = SPI_CRC_INITIALIZATION_ALL_ZERO_PATTERN;
  hspi1.Init.RxCRCInitializationPattern = SPI_CRC_INITIALIZATION_ALL_ZERO_PATTERN;
  hspi1.Init.MasterSSIdleness = SPI_MASTER_SS_IDLENESS_00CYCLE;
  hspi1.Init.MasterInterDataIdleness = SPI_MASTER_INTERDATA_IDLENESS_00CYCLE;
  hspi1.Init.MasterReceiverAutoSusp = SPI_MASTER_RX_AUTOSUSP_DISABLE;
  hspi1.Init.MasterKeepIOState = SPI_MASTER_KEEP_IO_STATE_DISABLE;
  hspi1.Init.IOSwap = SPI_IO_SWAP_DISABLE;
  if (HAL_SPI_Init(&hspi1) != HAL_OK)
  {
    Error_Handler();
  }

}

static void MX_SPI3_Init(void)
{

  /* SPI3 parameter configuration*/
  hspi3.Instance = SPI3;
  hspi3.Init.Mode = SPI_MODE_MASTER;
  hspi3.Init.Direction = SPI_DIRECTION_2LINES;
  hspi3.Init.DataSize = SPI_DATASIZE_8BIT;
  hspi3.Init.CLKPolarity = SPI_POLARITY_LOW;
  hspi3.Init.CLKPhase = SPI_PHASE_1EDGE;
  hspi3.Init.NSS = SPI_NSS_HARD_OUTPUT;
  hspi3.Init.BaudRatePrescaler = SPI_BAUDRATEPRESCALER_4;
  hspi3.Init.FirstBit = SPI_FIRSTBIT_MSB;
  hspi3.Init.TIMode = SPI_TIMODE_DISABLE;
  hspi3.Init.CRCCalculation = SPI_CRCCALCULATION_DISABLE;
  hspi3.Init.CRCPolynomial = 0x0;
  hspi3.Init.NSSPMode = SPI_NSS_PULSE_ENABLE;
  hspi3.Init.NSSPolarity = SPI_NSS_POLARITY_LOW;
  hspi3.Init.FifoThreshold = SPI_FIFO_THRESHOLD_01DATA;
  hspi3.Init.TxCRCInitializationPattern = SPI_CRC_INITIALIZATION_ALL_ZERO_PATTERN;
  hspi3.Init.RxCRCInitializationPattern = SPI_CRC_INITIALIZATION_ALL_ZERO_PATTERN;
  hspi3.Init.MasterSSIdleness = SPI_MASTER_SS_IDLENESS_00CYCLE;
  hspi3.Init.MasterInterDataIdleness = SPI_MASTER_INTERDATA_IDLENESS_00CYCLE;
  hspi3.Init.MasterReceiverAutoSusp = SPI_MASTER_RX_AUTOSUSP_DISABLE;
  hspi3.Init.MasterKeepIOState = SPI_MASTER_KEEP_IO_STATE_DISABLE;
  hspi3.Init.IOSwap = SPI_IO_SWAP_DISABLE;
  if (HAL_SPI_Init(&hspi3) != HAL_OK)
  {
    Error_Handler();
  }

}

static void MX_SPI4_Init(void)
{

  /* SPI4 parameter configuration*/
  hspi4.Instance = SPI4;
  hspi4.Init.Mode = SPI_MODE_MASTER;
  hspi4.Init.Direction = SPI_DIRECTION_2LINES;
  hspi4.Init.DataSize = SPI_DATASIZE_8BIT;
  hspi4.Init.CLKPolarity = SPI_POLARITY_HIGH;
  hspi4.Init.CLKPhase = SPI_PHASE_2EDGE;
  hspi4.Init.NSS = SPI_NSS_SOFT;
  hspi4.Init.BaudRatePrescaler = SPI_BAUDRATEPRESCALER_16;
  hspi4.Init.FirstBit = SPI_FIRSTBIT_MSB;
  hspi4.Init.TIMode = SPI_TIMODE_DISABLE;
  hspi4.Init.CRCCalculation = SPI_CRCCALCULATION_DISABLE;
  hspi4.Init.CRCPolynomial = 0x0;
  hspi4.Init.NSSPMode = SPI_NSS_PULSE_ENABLE;
  hspi4.Init.NSSPolarity = SPI_NSS_POLARITY_LOW;
  hspi4.Init.FifoThreshold = SPI_FIFO_THRESHOLD_01DATA;
  hspi4.Init.TxCRCInitializationPattern = SPI_CRC_INITIALIZATION_ALL_ZERO_PATTERN;
  hspi4.Init.RxCRCInitializationPattern = SPI_CRC_INITIALIZATION_ALL_ZERO_PATTERN;
  hspi4.Init.MasterSSIdleness = SPI_MASTER_SS_IDLENESS_00CYCLE;
  hspi4.Init.MasterInterDataIdleness = SPI_MASTER_INTERDATA_IDLENESS_00CYCLE;
  hspi4.Init.MasterReceiverAutoSusp = SPI_MASTER_RX_AUTOSUSP_DISABLE;
  hspi4.Init.MasterKeepIOState = SPI_MASTER_KEEP_IO_STATE_DISABLE;
  hspi4.Init.IOSwap = SPI_IO_SWAP_DISABLE;
  if (HAL_SPI_Init(&hspi4) != HAL_OK)
  {
    Error_Handler();
  }

}

static void MX_SPI5_Init(void)
{

  /* SPI5 parameter configuration*/
  hspi5.Instance = SPI5;
  hspi5.Init.Mode = SPI_MODE_MASTER;
  hspi5.Init.Direction = SPI_DIRECTION_2LINES;
  hspi5.Init.DataSize = SPI_DATASIZE_8BIT;
  hspi5.Init.CLKPolarity = SPI_POLARITY_LOW;
  hspi5.Init.CLKPhase = SPI_PHASE_2EDGE;
  hspi5.Init.NSS = SPI_NSS_HARD_OUTPUT;
  hspi5.Init.BaudRatePrescaler = SPI_BAUDRATEPRESCALER_64;
  hspi5.Init.FirstBit = SPI_FIRSTBIT_MSB;
  hspi5.Init.TIMode = SPI_TIMODE_DISABLE;
  hspi5.Init.CRCCalculation = SPI_CRCCALCULATION_DISABLE;
  hspi5.Init.CRCPolynomial = 0x0;
  hspi5.Init.NSSPMode = SPI_NSS_PULSE_ENABLE;
  hspi5.Init.NSSPolarity = SPI_NSS_POLARITY_LOW;
  hspi5.Init.FifoThreshold = SPI_FIFO_THRESHOLD_01DATA;
  hspi5.Init.TxCRCInitializationPattern = SPI_CRC_INITIALIZATION_ALL_ZERO_PATTERN;
  hspi5.Init.RxCRCInitializationPattern = SPI_CRC_INITIALIZATION_ALL_ZERO_PATTERN;
  hspi5.Init.MasterSSIdleness = SPI_MASTER_SS_IDLENESS_00CYCLE;
  hspi5.Init.MasterInterDataIdleness = SPI_MASTER_INTERDATA_IDLENESS_00CYCLE;
  hspi5.Init.MasterReceiverAutoSusp = SPI_MASTER_RX_AUTOSUSP_DISABLE;
  hspi5.Init.MasterKeepIOState = SPI_MASTER_KEEP_IO_STATE_ENABLE;
  hspi5.Init.IOSwap = SPI_IO_SWAP_DISABLE;
  if (HAL_SPI_Init(&hspi5) != HAL_OK)
  {
    Error_Handler();
  }

}

static void MX_TIM2_Init(void)
{

  TIM_Encoder_InitTypeDef sConfig = {0};
  TIM_MasterConfigTypeDef sMasterConfig = {0};

  htim2.Instance = TIM2;
  htim2.Init.Prescaler = 0;
  htim2.Init.CounterMode = TIM_COUNTERMODE_UP;
  htim2.Init.Period = 4096;
  htim2.Init.ClockDivision = TIM_CLOCKDIVISION_DIV1;
  htim2.Init.AutoReloadPreload = TIM_AUTORELOAD_PRELOAD_DISABLE;
  sConfig.EncoderMode = TIM_ENCODERMODE_TI1;
  sConfig.IC1Polarity = TIM_ICPOLARITY_RISING;
  sConfig.IC1Selection = TIM_ICSELECTION_DIRECTTI;
  sConfig.IC1Prescaler = TIM_ICPSC_DIV1;
  sConfig.IC1Filter = 5;
  sConfig.IC2Polarity = TIM_ICPOLARITY_RISING;
  sConfig.IC2Selection = TIM_ICSELECTION_DIRECTTI;
  sConfig.IC2Prescaler = TIM_ICPSC_DIV1;
  sConfig.IC2Filter = 5;
  if (HAL_TIM_Encoder_Init(&htim2, &sConfig) != HAL_OK)
  {
    Error_Handler();
  }
  sMasterConfig.MasterOutputTrigger = TIM_TRGO_RESET;
  sMasterConfig.MasterSlaveMode = TIM_MASTERSLAVEMODE_DISABLE;
  if (HAL_TIMEx_MasterConfigSynchronization(&htim2, &sMasterConfig) != HAL_OK)
  {
    Error_Handler();
  }

}

static void MX_TIM3_Init(void)
{

  TIM_Encoder_InitTypeDef sConfig = {0};
  TIM_MasterConfigTypeDef sMasterConfig = {0};

  htim3.Instance = TIM3;
  htim3.Init.Prescaler = 0;
  htim3.Init.CounterMode = TIM_COUNTERMODE_UP;
  htim3.Init.Period = 4096;
  htim3.Init.ClockDivision = TIM_CLOCKDIVISION_DIV1;
  htim3.Init.AutoReloadPreload = TIM_AUTORELOAD_PRELOAD_DISABLE;
  sConfig.EncoderMode = TIM_ENCODERMODE_TI1;
  sConfig.IC1Polarity = TIM_ICPOLARITY_RISING;
  sConfig.IC1Selection = TIM_ICSELECTION_DIRECTTI;
  sConfig.IC1Prescaler = TIM_ICPSC_DIV1;
  sConfig.IC1Filter = 5;
  sConfig.IC2Polarity = TIM_ICPOLARITY_RISING;
  sConfig.IC2Selection = TIM_ICSELECTION_DIRECTTI;
  sConfig.IC2Prescaler = TIM_ICPSC_DIV1;
  sConfig.IC2Filter = 5;
  if (HAL_TIM_Encoder_Init(&htim3, &sConfig) != HAL_OK)
  {
    Error_Handler();
  }
  sMasterConfig.MasterOutputTrigger = TIM_TRGO_RESET;
  sMasterConfig.MasterSlaveMode = TIM_MASTERSLAVEMODE_DISABLE;
  if (HAL_TIMEx_MasterConfigSynchronization(&htim3, &sMasterConfig) != HAL_OK)
  {
    Error_Handler();
  }

}

static void MX_TIM4_Init(void)
{

  TIM_Encoder_InitTypeDef sConfig = {0};
  TIM_MasterConfigTypeDef sMasterConfig = {0};

  htim4.Instance = TIM4;
  htim4.Init.Prescaler = 0;
  htim4.Init.CounterMode = TIM_COUNTERMODE_UP;
  htim4.Init.Period = 4096;
  htim4.Init.ClockDivision = TIM_CLOCKDIVISION_DIV1;
  htim4.Init.AutoReloadPreload = TIM_AUTORELOAD_PRELOAD_DISABLE;
  sConfig.EncoderMode = TIM_ENCODERMODE_TI1;
  sConfig.IC1Polarity = TIM_ICPOLARITY_RISING;
  sConfig.IC1Selection = TIM_ICSELECTION_DIRECTTI;
  sConfig.IC1Prescaler = TIM_ICPSC_DIV1;
  sConfig.IC1Filter = 5;
  sConfig.IC2Polarity = TIM_ICPOLARITY_RISING;
  sConfig.IC2Selection = TIM_ICSELECTION_DIRECTTI;
  sConfig.IC2Prescaler = TIM_ICPSC_DIV1;
  sConfig.IC2Filter = 5;
  if (HAL_TIM_Encoder_Init(&htim4, &sConfig) != HAL_OK)
  {
    Error_Handler();
  }
  sMasterConfig.MasterOutputTrigger = TIM_TRGO_RESET;
  sMasterConfig.MasterSlaveMode = TIM_MASTERSLAVEMODE_DISABLE;
  if (HAL_TIMEx_MasterConfigSynchronization(&htim4, &sMasterConfig) != HAL_OK)
  {
    Error_Handler();
  }

}

static void MX_UART4_Init(void)
{

  huart4.Instance = UART4;
  huart4.Init.BaudRate = 115200;
  huart4.Init.WordLength = UART_WORDLENGTH_8B;
  huart4.Init.StopBits = UART_STOPBITS_1;
  huart4.Init.Parity = UART_PARITY_NONE;
  huart4.Init.Mode = UART_MODE_TX_RX;
  huart4.Init.HwFlowCtl = UART_HWCONTROL_NONE;
  huart4.Init.OverSampling = UART_OVERSAMPLING_16;
  huart4.Init.OneBitSampling = UART_ONE_BIT_SAMPLE_DISABLE;
  huart4.Init.ClockPrescaler = UART_PRESCALER_DIV1;
  huart4.AdvancedInit.AdvFeatureInit = UART_ADVFEATURE_NO_INIT;
  if (HAL_UART_Init(&huart4) != HAL_OK)
  {
    Error_Handler();
  }
  if (HAL_UARTEx_SetTxFifoThreshold(&huart4, UART_TXFIFO_THRESHOLD_1_2) != HAL_OK)
  {
    Error_Handler();
  }
  if (HAL_UARTEx_SetRxFifoThreshold(&huart4, UART_RXFIFO_THRESHOLD_1_2) != HAL_OK)
  {
    Error_Handler();
  }
  if (HAL_UARTEx_EnableFifoMode(&huart4) != HAL_OK)
  {
    Error_Handler();
  }

}

static void MX_USART2_UART_Init(void)
{

husart2.Instance = USART2;
husart2.Init.BaudRate = 115200;
husart2.Init.WordLength = USART_WORDLENGTH_8B;
husart2.Init.StopBits = USART_STOPBITS_1;
husart2.Init.Parity = USART_PARITY_NONE;
husart2.Init.Mode = USART_MODE_TX_RX;
husart2.Init.CLKPolarity = USART_POLARITY_LOW;
husart2.Init.CLKPhase = USART_PHASE_1EDGE;
husart2.Init.CLKLastBit = USART_LASTBIT_DISABLE;
husart2.Init.ClockPrescaler = USART_PRESCALER_DIV1;
husart2.SlaveMode = USART_SLAVEMODE_DISABLE;
	  if (HAL_USART_Init(&husart2) != HAL_OK)
  {
    Error_Handler();
  }
  if (HAL_USARTEx_SetTxFifoThreshold(&husart2, USART_TXFIFO_THRESHOLD_1_8) != HAL_OK)
  {
    Error_Handler();
  }
  if (HAL_USARTEx_SetRxFifoThreshold(&husart2, USART_RXFIFO_THRESHOLD_1_8) != HAL_OK)
  {
    Error_Handler();
  }
  if (HAL_USARTEx_DisableFifoMode(&husart2) != HAL_OK)
  {
    Error_Handler();
  }

}

static void MX_USART3_UART_Init(void)
{

  huart3.Instance = USART3;
  huart3.Init.BaudRate = 115200;
  huart3.Init.WordLength = UART_WORDLENGTH_8B;
  huart3.Init.StopBits = UART_STOPBITS_1;
  huart3.Init.Parity = UART_PARITY_NONE;
  huart3.Init.Mode = UART_MODE_TX_RX;
  huart3.Init.HwFlowCtl = UART_HWCONTROL_NONE;
  huart3.Init.OverSampling = UART_OVERSAMPLING_16;
  huart3.Init.OneBitSampling = UART_ONE_BIT_SAMPLE_DISABLE;
  huart3.Init.ClockPrescaler = UART_PRESCALER_DIV1;
  huart3.AdvancedInit.AdvFeatureInit = UART_ADVFEATURE_NO_INIT;
  if (HAL_UART_Init(&huart3) != HAL_OK)
  {
    Error_Handler();
  }
  if (HAL_UARTEx_SetTxFifoThreshold(&huart3, UART_TXFIFO_THRESHOLD_1_8) != HAL_OK)
  {
    Error_Handler();
  }
  if (HAL_UARTEx_SetRxFifoThreshold(&huart3, UART_RXFIFO_THRESHOLD_1_8) != HAL_OK)
  {
    Error_Handler();
  }
  if (HAL_UARTEx_DisableFifoMode(&huart3) != HAL_OK)
  {
    Error_Handler();
  }

}

static void MX_USB_OTG_FS_PCD_Init(void)
{

  hpcd_USB_OTG_FS.Instance = USB_OTG_FS;
  hpcd_USB_OTG_FS.Init.dev_endpoints = 9;
  hpcd_USB_OTG_FS.Init.speed = PCD_SPEED_FULL;
  hpcd_USB_OTG_FS.Init.dma_enable = DISABLE;
  hpcd_USB_OTG_FS.Init.phy_itface = PCD_PHY_EMBEDDED;
  hpcd_USB_OTG_FS.Init.Sof_enable = ENABLE;
  hpcd_USB_OTG_FS.Init.low_power_enable = DISABLE;
  hpcd_USB_OTG_FS.Init.lpm_enable = DISABLE;
  hpcd_USB_OTG_FS.Init.battery_charging_enable = ENABLE;
  hpcd_USB_OTG_FS.Init.vbus_sensing_enable = ENABLE;
  hpcd_USB_OTG_FS.Init.use_dedicated_ep1 = DISABLE;
  if (HAL_PCD_Init(&hpcd_USB_OTG_FS) != HAL_OK)
  {
    Error_Handler();
  }

}

static void MX_DMA_Init(void)
{

  /* DMA controller clock enable */
  __HAL_RCC_DMA1_CLK_ENABLE();

  /* DMA interrupt init */
  /* DMA1_Stream0_IRQn interrupt configuration */
  HAL_NVIC_SetPriority(DMA1_Stream0_IRQn, 5, 0);
  HAL_NVIC_EnableIRQ(DMA1_Stream0_IRQn);
  /* DMA1_Stream4_IRQn interrupt configuration */
  HAL_NVIC_SetPriority(DMA1_Stream4_IRQn, 5, 0);
  HAL_NVIC_EnableIRQ(DMA1_Stream4_IRQn);

}

static void MX_GPIO_Init(void)
{
  GPIO_InitTypeDef GPIO_InitStruct = {0};

  /* GPIO Ports Clock Enable */
  __HAL_RCC_GPIOE_CLK_ENABLE();
  __HAL_RCC_GPIOC_CLK_ENABLE();
  __HAL_RCC_GPIOF_CLK_ENABLE();
  __HAL_RCC_GPIOH_CLK_ENABLE();
  __HAL_RCC_GPIOA_CLK_ENABLE();
  __HAL_RCC_GPIOB_CLK_ENABLE();
  __HAL_RCC_GPIOG_CLK_ENABLE();
  __HAL_RCC_GPIOD_CLK_ENABLE();

  /*Configure GPIO pin Output Level */
  HAL_GPIO_WritePin(GPIOE, ETH_NSS_Pin|USER_LED_Y_Pin, GPIO_PIN_RESET);

  /*Configure GPIO pin Output Level */
  HAL_GPIO_WritePin(GPIOF, GPIO_PIN_2, GPIO_PIN_RESET);

  /*Configure GPIO pin Output Level */
  HAL_GPIO_WritePin(GPIOB, USER_LED_G_Pin|ETH_RSTN_Pin|USER_LED_R_Pin, GPIO_PIN_RESET);

  /*Configure GPIO pin Output Level */
  HAL_GPIO_WritePin(GPIOD, GPIO_PIN_10, GPIO_PIN_RESET);

  /*Configure GPIO pin Output Level */
  HAL_GPIO_WritePin(GPIOG, LCD2_DCX_Pin|LCD2_RSVD_Pin, GPIO_PIN_RESET);

  /*Configure GPIO pin Output Level */
  HAL_GPIO_WritePin(GPIOC, LCD1_DCX_Pin|LCD1_RSVD_Pin, GPIO_PIN_RESET);

  /*Configure GPIO pin Output Level */
  HAL_GPIO_WritePin(GPIOD, GPIO_PIN_4, GPIO_PIN_SET);

  /*Configure GPIO pin : PG_Pin */
  GPIO_InitStruct.Pin = PG_Pin;
  GPIO_InitStruct.Mode = GPIO_MODE_INPUT;
  GPIO_InitStruct.Pull = GPIO_PULLUP;
  HAL_GPIO_Init(PG_GPIO_Port, &GPIO_InitStruct);

  /*Configure GPIO pin : ETH_NSS_Pin */
  GPIO_InitStruct.Pin = ETH_NSS_Pin;
  GPIO_InitStruct.Mode = GPIO_MODE_OUTPUT_PP;
  GPIO_InitStruct.Pull = GPIO_PULLUP;
  GPIO_InitStruct.Speed = GPIO_SPEED_FREQ_LOW;
  HAL_GPIO_Init(ETH_NSS_GPIO_Port, &GPIO_InitStruct);

  /*Configure GPIO pin : PC13 */
  GPIO_InitStruct.Pin = GPIO_PIN_13;
  GPIO_InitStruct.Mode = GPIO_MODE_INPUT;
  GPIO_InitStruct.Pull = GPIO_NOPULL;
  HAL_GPIO_Init(GPIOC, &GPIO_InitStruct);

  /*Configure GPIO pin : PF2 */
  GPIO_InitStruct.Pin = GPIO_PIN_2;
  GPIO_InitStruct.Mode = GPIO_MODE_OUTPUT_PP;
  GPIO_InitStruct.Pull = GPIO_NOPULL;
  GPIO_InitStruct.Speed = GPIO_SPEED_FREQ_LOW;
  HAL_GPIO_Init(GPIOF, &GPIO_InitStruct);

  /*Configure GPIO pins : USER_LED_G_Pin ETH_RSTN_Pin USER_LED_R_Pin */
  GPIO_InitStruct.Pin = USER_LED_G_Pin|ETH_RSTN_Pin|USER_LED_R_Pin;
  GPIO_InitStruct.Mode = GPIO_MODE_OUTPUT_PP;
  GPIO_InitStruct.Pull = GPIO_NOPULL;
  GPIO_InitStruct.Speed = GPIO_SPEED_FREQ_LOW;
  HAL_GPIO_Init(GPIOB, &GPIO_InitStruct);

  /*Configure GPIO pins : STAT1_Pin STAT2_Pin */
  GPIO_InitStruct.Pin = STAT1_Pin|STAT2_Pin;
  GPIO_InitStruct.Mode = GPIO_MODE_INPUT;
  GPIO_InitStruct.Pull = GPIO_PULLUP;
  HAL_GPIO_Init(GPIOG, &GPIO_InitStruct);

  /*Configure GPIO pin : ETH_INTn_Pin */
  GPIO_InitStruct.Pin = ETH_INTn_Pin;
  GPIO_InitStruct.Mode = GPIO_MODE_INPUT;
  GPIO_InitStruct.Pull = GPIO_NOPULL;
  HAL_GPIO_Init(ETH_INTn_GPIO_Port, &GPIO_InitStruct);

  /*Configure GPIO pins : PD10 PD4 */
  GPIO_InitStruct.Pin = GPIO_PIN_10|GPIO_PIN_4;
  GPIO_InitStruct.Mode = GPIO_MODE_OUTPUT_PP;
  GPIO_InitStruct.Pull = GPIO_NOPULL;
  GPIO_InitStruct.Speed = GPIO_SPEED_FREQ_LOW;
  HAL_GPIO_Init(GPIOD, &GPIO_InitStruct);

  /*Configure GPIO pins : LCD2_DCX_Pin LCD2_RSVD_Pin */
  GPIO_InitStruct.Pin = LCD2_DCX_Pin|LCD2_RSVD_Pin;
  GPIO_InitStruct.Mode = GPIO_MODE_OUTPUT_PP;
  GPIO_InitStruct.Pull = GPIO_NOPULL;
  GPIO_InitStruct.Speed = GPIO_SPEED_FREQ_LOW;
  HAL_GPIO_Init(GPIOG, &GPIO_InitStruct);

  /*Configure GPIO pin : PG7 */
  GPIO_InitStruct.Pin = GPIO_PIN_7;
  GPIO_InitStruct.Mode = GPIO_MODE_IT_RISING;
  GPIO_InitStruct.Pull = GPIO_NOPULL;
  HAL_GPIO_Init(GPIOG, &GPIO_InitStruct);

  /*Configure GPIO pins : LCD1_DCX_Pin LCD1_RSVD_Pin */
  GPIO_InitStruct.Pin = LCD1_DCX_Pin|LCD1_RSVD_Pin;
  GPIO_InitStruct.Mode = GPIO_MODE_OUTPUT_PP;
  GPIO_InitStruct.Pull = GPIO_NOPULL;
  GPIO_InitStruct.Speed = GPIO_SPEED_FREQ_LOW;
  HAL_GPIO_Init(GPIOC, &GPIO_InitStruct);

  /*Configure GPIO pin : USER_LED_Y_Pin */
  GPIO_InitStruct.Pin = USER_LED_Y_Pin;
  GPIO_InitStruct.Mode = GPIO_MODE_OUTPUT_PP;
  GPIO_InitStruct.Pull = GPIO_NOPULL;
  GPIO_InitStruct.Speed = GPIO_SPEED_FREQ_LOW;
  HAL_GPIO_Init(USER_LED_Y_GPIO_Port, &GPIO_InitStruct);

}

/* USER CODE BEGIN 4 */
void FillRectHandle(){
	fillRectHandle.Instance = DMA2D;

	fillRectHandle.Init.Mode = DMA2D_R2M;
	fillRectHandle.Init.ColorMode = DMA2D_OUTPUT_ARGB1555;
	fillRectHandle.Init.OutputOffset = 0;
}

void BlendImageHandle(){
	blendImageHandle.Instance = DMA2D;

	blendImageHandle.Init.Mode = DMA2D_M2M_BLEND;
	blendImageHandle.Init.ColorMode = DMA2D_OUTPUT_RGB565;
	//blendImageHandle.Init.BytesSwap = DMA2D_BYTES_SWAP;

	// Foreground
	blendImageHandle.LayerCfg[1].AlphaMode = DMA2D_REGULAR_ALPHA;
	blendImageHandle.LayerCfg[1].InputColorMode = DMA2D_INPUT_ARGB1555;
	blendImageHandle.LayerCfg[1].InputOffset = 0;
	blendImageHandle.LayerCfg[1].RedBlueSwap = DMA2D_RB_REGULAR;
	blendImageHandle.LayerCfg[1].AlphaInverted = DMA2D_REGULAR_ALPHA;

	// Background
	blendImageHandle.LayerCfg[0].AlphaMode = DMA2D_NO_MODIF_ALPHA;
	blendImageHandle.LayerCfg[0].InputColorMode = DMA2D_INPUT_RGB565;
	blendImageHandle.LayerCfg[0].RedBlueSwap = DMA2D_RB_REGULAR;
}

void DMA2D_FillRect(uint16_t *screen_buffer, uint32_t color, uint32_t x, uint32_t y, uint32_t width, uint32_t height, uint32_t buffer_width) {

	fillRectHandle.Init.OutputOffset = buffer_width - width;

	HAL_DMA2D_Init(&fillRectHandle);
	HAL_DMA2D_Start(&fillRectHandle, color,
			(uint32_t) screen_buffer + (x + y * buffer_width) * 2, width, height);

	HAL_DMA2D_PollForTransfer(&fillRectHandle, 200);
}

void DMA2D_BlendImage(uint16_t *screen_buffer, uint32_t data, uint32_t x, uint32_t y, uint32_t width, uint32_t height, uint32_t buffer_width) {
	uint32_t destination = (uint32_t) screen_buffer + (x + y * LCD_WIDTH) * 2;

	blendImageHandle.Init.OutputOffset = buffer_width - width;
	blendImageHandle.LayerCfg[0].InputOffset = buffer_width - width;

	HAL_DMA2D_Init(&blendImageHandle);
	HAL_DMA2D_ConfigLayer(&blendImageHandle, 1);
	HAL_DMA2D_ConfigLayer(&blendImageHandle, 0);

	HAL_DMA2D_BlendingStart(&blendImageHandle, data, destination, destination, width,
			height);

	HAL_DMA2D_PollForTransfer(&blendImageHandle, 200);
}

void updateChargeStatus(){
	uint8_t statOne = HAL_GPIO_ReadPin(GPIOG, STAT1_Pin);
	uint8_t statTwo = HAL_GPIO_ReadPin(GPIOG, STAT2_Pin);

	if(statOne == 1 && statTwo == 1){
		HAL_GPIO_WritePin(GPIOE, USER_LED_Y_Pin, GPIO_PIN_SET);
		HAL_GPIO_WritePin(GPIOB, USER_LED_G_Pin, GPIO_PIN_SET);
	}else if(statOne == 0 && statTwo == 1){
		HAL_GPIO_WritePin(GPIOE, USER_LED_Y_Pin, GPIO_PIN_SET);
		HAL_GPIO_WritePin(GPIOB, USER_LED_G_Pin, GPIO_PIN_RESET);
	}else if(statOne == 1 && statTwo == 0){
		HAL_GPIO_WritePin(GPIOE, USER_LED_Y_Pin, GPIO_PIN_RESET);
		HAL_GPIO_WritePin(GPIOB, USER_LED_G_Pin, GPIO_PIN_SET);
	}else{
		HAL_GPIO_WritePin(GPIOE, USER_LED_Y_Pin, GPIO_PIN_RESET);
		HAL_GPIO_WritePin(GPIOB, USER_LED_G_Pin, GPIO_PIN_RESET);
	}
}
/* USER CODE END 4 */

void StartCommTask(void *argument)
{
  /* USER CODE BEGIN 5 */
	EthInit(&hspi4);

#ifdef DO_LOOP_MEASURE
	//the timer counts 10k times a second
	uint32_t start_time = 0;
	uint32_t end_time = 0;
	uint32_t loop_index = 0;
#define AVG_ARRAY_LEN 100
	uint32_t loop_times[AVG_ARRAY_LEN];
	float max_loop_time = 0.0;
	float average_loop_time = 0.0;
	char serial_buffer[10];
#endif

	/* Infinite loop */
	for (ever) {
#ifdef DO_LOOP_MEASURE
		start_time = hrtim_count;
#endif
		loop_udps(5050);

		updateChargeStatus();

#ifdef DO_LOOP_MEASURE

		end_time = hrtim_count;

		loop_times[loop_index] = end_time - start_time;
		loop_index++;

		//calculate average and reset index when reached end of array
		if(loop_index >= 100){
			uint32_t sum = 0;
			for(int i = 0; i < AVG_ARRAY_LEN; i++){
				sum += loop_times[i];
			}
			average_loop_time = ((float)sum / AVG_ARRAY_LEN) * 0.0001;
			loop_index = 0;
			sprintf(serial_buffer, "%7d\n\r", (int)(average_loop_time * 1000000));
			HAL_UART_Transmit(&huart3, (uint8_t*)serial_buffer, 10, 10);
		}

		//check if it is the max time
		if(end_time - start_time > max_loop_time){
			max_loop_time = (float)(end_time - start_time) * 0.0001;
		}
#endif
	}
  /* USER CODE END 5 */
}

void StartLCDDisplays(void *argument)
{
  /* USER CODE BEGIN StartLCDDisplays */
	uint8_t lcd1_lastx;
	uint8_t lcd1_lasty;
	uint8_t lcd2_lastx;
	uint8_t lcd2_lasty;

	uint8_t lcd1_x = 50;
	uint8_t lcd1_y = 50;
	int8_t lcd1_x_step = 0;
	int8_t lcd1_y_step = 0;

	uint8_t lcd2_x = 50;
	uint8_t lcd2_y = 50;
	int8_t lcd2_x_step = 0;
	int8_t lcd2_y_step = 0;

	DMA2D_FillRect(lcd1_screen_buffer, 0xFFFFFFFF, 0, 0, 240, 240, LCD_WIDTH);
	ST7789_writeScreen(lcd1, lcd1_screen_buffer);

	DMA2D_FillRect(lcd2_screen_buffer, 0xFFFFFFFF, 0, 0, 240, 240, LCD_WIDTH);
	ST7789_writeScreen(lcd2, lcd2_screen_buffer);

	/* Infinite loop */
	for (ever) {
		//wait for the software timer to signal that it is time to refresh the LCD
		osSemaphoreAcquire(lcdDisplaysTaskSemHandle, osWaitForever);

		lcd1_x_step = (lcd1_x_t - lcd1_x) / 2;
		lcd1_y_step = (lcd1_y_t - lcd1_y) / 2;

		lcd2_x_step = (lcd2_x_t - lcd2_x) / 2;
		lcd2_y_step = (lcd2_y_t - lcd2_y) / 2;

		if(blink > 0){
			while(oneTransmitting);
			DMA2D_FillRect(lcd1_screen_buffer, 0x00000000, 0, 0, 240, 240, LCD_WIDTH);
			ST7789_writeScreen(lcd1, lcd1_screen_buffer);

			while(threeTransmitting);
			DMA2D_FillRect(lcd2_screen_buffer, 0x00000000, 0, 0, 240, 240, LCD_WIDTH);
			ST7789_writeScreen(lcd2, lcd2_screen_buffer);

			blink -= 1;

			if(blink == 0){
				DMA2D_FillRect(lcd1_screen_buffer, 0xFFFFFFFF, 0, 0, 240, 240, LCD_WIDTH);
				DMA2D_FillRect(lcd2_screen_buffer, 0xFFFFFFFF, 0, 0, 240, 240, LCD_WIDTH);
			}
		}else{
			if (abs(lcd1_x_step) > 2 || abs(lcd1_y_step) > 2) {
				lcd1_lastx = lcd1_x;
				lcd1_lasty = lcd1_y;

				lcd1_x += lcd1_x_step;
				lcd1_y += lcd1_y_step;
			}

			if (abs(lcd2_x_step) > 2 || abs(lcd2_y_step) > 2) {
				lcd2_lastx = lcd2_x;
				lcd2_lasty = lcd2_y;

				lcd2_x += lcd2_x_step;
				lcd2_y += lcd2_y_step;
			}

			while(oneTransmitting);
			DMA2D_FillRect(lcd1_screen_buffer, 0xFFFFFFFF, lcd1_lastx, lcd1_lasty, IMAGE_WIDTH, IMAGE_HEIGHT, LCD_WIDTH);
			DMA2D_BlendImage(lcd1_screen_buffer, (uint32_t) green_eye_80x80, lcd1_x, lcd1_y, IMAGE_WIDTH, IMAGE_HEIGHT, LCD_WIDTH);
			DMA2D_BlendImage(lcd1_screen_buffer, (uint32_t) front_image, 0, 0, 240, 240, LCD_WIDTH);
			ST7789_writeScreen(lcd1, lcd1_screen_buffer);

			while(threeTransmitting);
			DMA2D_FillRect(lcd2_screen_buffer, 0xFFFFFFFF, lcd2_lastx, lcd2_lasty, IMAGE_WIDTH, IMAGE_HEIGHT, LCD_WIDTH);
			DMA2D_BlendImage(lcd2_screen_buffer, (uint32_t) green_eye_80x80, lcd2_x, lcd2_y, IMAGE_WIDTH, IMAGE_HEIGHT, LCD_WIDTH);
			DMA2D_BlendImage(lcd2_screen_buffer, (uint32_t) front_image, 0, 0, 240, 240, LCD_WIDTH);
			ST7789_writeScreen(lcd2, lcd2_screen_buffer);
		}
	}
  /* USER CODE END StartLCDDisplays */
}

void StartMotorOutput(void *argument)
{
  /* USER CODE BEGIN StartMotorOutput */
	/* Infinite loop */
	for (;;) {
		osSemaphoreAcquire(pidStepTaskSemHandle, osWaitForever);

		for(int i = 0; i < MAX_PACKAGES; i++){
			if(Packages[i] != 0){
				Package_updateSensorValue(Packages[i]);
				Package_StepPID(Packages[i]);
			}
		}
	}
  /* USER CODE END StartMotorOutput */
}

/* Timer_LCD_cb function */
void Timer_LCD_cb(void *argument)
{
  /* USER CODE BEGIN Timer_LCD_cb */
  osSemaphoreRelease(lcdDisplaysTaskSemHandle);
  /* USER CODE END Timer_LCD_cb */
}

/* Timer_PID_cb function */
void Timer_PID_cb(void *argument)
{
  /* USER CODE BEGIN Timer_PID_cb */
	osSemaphoreRelease(pidStepTaskSemHandle);
  /* USER CODE END Timer_PID_cb */
}

/* MPU Configuration */

void MPU_Config(void)
{

  /* Disables the MPU */
  HAL_MPU_Disable();
  /* Enables the MPU */
  HAL_MPU_Enable(MPU_PRIVILEGED_DEFAULT);

}

void HAL_TIM_PeriodElapsedCallback(TIM_HandleTypeDef *htim)
{
  if (htim->Instance == TIM1) {
    HAL_IncTick();
  }
}

void Error_Handler(void)
{
}

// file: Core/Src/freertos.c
/* USER CODE BEGIN Header */
/**
  ******************************************************************************
  * File Name          : freertos.c
  * Description        : Code for freertos applications
  ******************************************************************************
  * @attention
  *
  * <h2><center>&copy; Copyright (c) 2019 STMicroelectronics.
  * All rights reserved.</center></h2>
  *
  * This software component is licensed by ST under Ultimate Liberty license
  * SLA0044, the "License"; You may not use this file except in compliance with
  * the License. You may obtain a copy of the License at:
  *                             www.st.com/SLA0044
  *
  ******************************************************************************
  */
/* USER CODE END Header */

#include "FreeRTOS.h"
#include "task.h"
#include "main.h"

/* Hook prototypes */
void configureTimerForRunTimeStats(void);
unsigned long getRunTimeCounterValue(void);

/* USER CODE BEGIN 1 */
/* Functions needed when configGENERATE_RUN_TIME_STATS is on */
__weak void configureTimerForRunTimeStats(void)
{

}

__weak unsigned long getRunTimeCounterValue(void)
{
return 0;
}
/* USER CODE END 1 */
